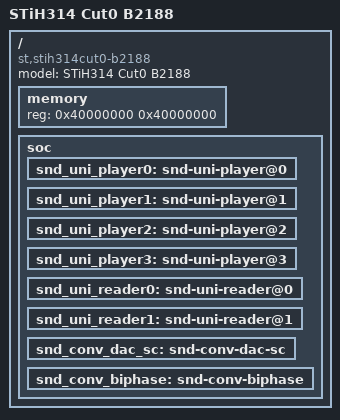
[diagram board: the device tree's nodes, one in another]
/*
 * Copyright (C) 2014 STMicroelectronics (R&D) Limited.
 * Author: Maxime Coquelin <maxime.coquelin@st.com>
 *
 * This program is free software; you can redistribute it and/or modify
 * it under the terms of the GNU General Public License version 2 as
 * published by the Free Software Foundation.
 */
/dts-v1/;
#include "stih410.dtsi"
#include "stihxxx-b2188.dtsi"
/ {
	model = "STiH314 Cut0 B2188";
	compatible = "st,stih314cut0-b2188", "st,stih314cut0", "st,stih410";

	memory {
		device_type = "memory";
		reg = <0x40000000 0x40000000>;
	};

	soc {
		/* Uniperipheral*/
		snd_uni_player0: snd-uni-player@0 {
			status = "okay";
		};

		snd_uni_player1: snd-uni-player@1 {
			status = "okay";
		};

		snd_uni_player2: snd-uni-player@2 {
			status = "okay";
		};

		snd_uni_player3: snd-uni-player@3 {
			status = "okay";
		};

		snd_uni_reader0: snd-uni-reader@0 {
			status = "okay";
		};

		snd_uni_reader1: snd-uni-reader@1 {
			status = "okay";
		};

		snd_conv_dac_sc: snd-conv-dac-sc {
			status = "okay";
		};

		snd_conv_biphase: snd-conv-biphase {
			status = "okay";
		};
	};
};
